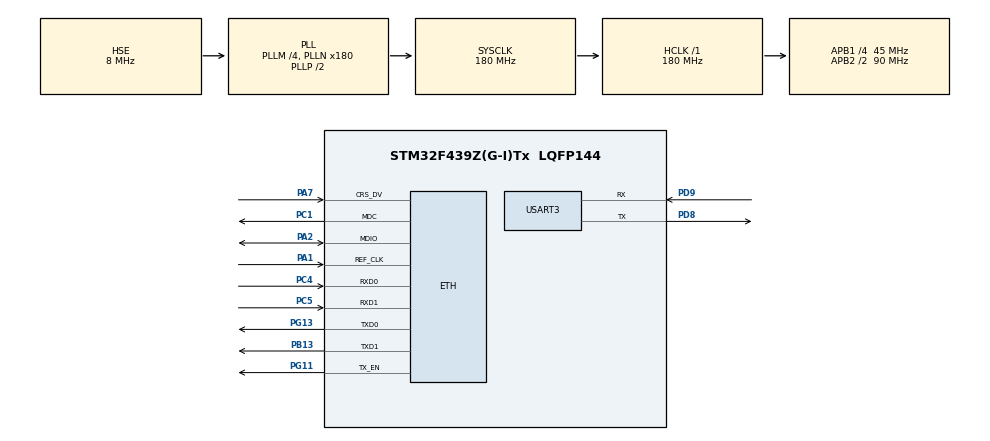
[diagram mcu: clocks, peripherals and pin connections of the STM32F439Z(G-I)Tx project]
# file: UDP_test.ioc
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ETH.MediaInterface=HAL_ETH_RMII_MODE
LWIP.BSP.number=1
LWIP.GATEWAY_ADDRESS=192.168.001.001
LWIP.IP_ADDRESS=192.168.001.102
LWIP.LWIP_DHCP=0
LWIP.LWIP_NETIF_STATUS_CALLBACK=1
LWIP.MEM_SIZE=16000
LWIP.NETMASK_ADDRESS=255.255.255.000
LWIP.Version=v2.1.2_Cube
LWIP0.BSP.STBoard=false
LWIP0.BSP.api=BSP_COMPONENT_DRIVER
LWIP0.BSP.component=LAN8742
LWIP0.BSP.instance=LAN8742
LWIP0.BSP.name=Driver_PHY
LWIP0.BSP.semaphore=S_LAN8742
LWIP0.BSP.solution=LAN8742
Mcu.Family=STM32F4
Mcu.Name=STM32F439Z(G-I)Tx
Mcu.Package=LQFP144
NVIC.ETH_IRQn=true\:0\:0\:false\:false\:true\:true\:true\:true
NVIC.PriorityGroup=NVIC_PRIORITYGROUP_4
NVIC.USART3_IRQn=true\:0\:0\:false\:false\:true\:true\:true\:true
PA1.Mode=RMII
PA1.Signal=ETH_REF_CLK
PA13.Mode=Serial_Wire
PA13.Signal=SYS_JTMS-SWDIO
PA14.Mode=Serial_Wire
PA14.Signal=SYS_JTCK-SWCLK
PA2.Mode=RMII
PA2.Signal=ETH_MDIO
PA7.Mode=RMII
PA7.Signal=ETH_CRS_DV
PB13.Mode=RMII
PB13.Signal=ETH_TXD1
PC1.Mode=RMII
PC1.Signal=ETH_MDC
PC14/OSC32_IN.Mode=LSE-External-Oscillator
PC14/OSC32_IN.Signal=RCC_OSC32_IN
PC15/OSC32_OUT.Mode=LSE-External-Oscillator
PC15/OSC32_OUT.Signal=RCC_OSC32_OUT
PC4.Mode=RMII
PC4.Signal=ETH_RXD0
PC5.Mode=RMII
PC5.Signal=ETH_RXD1
PD8.Mode=Asynchronous
PD8.Signal=USART3_TX
PD9.Mode=Asynchronous
PD9.Signal=USART3_RX
PG11.Mode=RMII
PG11.Signal=ETH_TX_EN
PG13.Mode=RMII
PG13.Signal=ETH_TXD0
PH0/OSC_IN.Mode=HSE-External-Clock-Source
PH0/OSC_IN.Signal=RCC_OSC_IN
PH1/OSC_OUT.Mode=HSE-External-Clock-Source
PH1/OSC_OUT.Signal=RCC_OSC_OUT
ProjectManager.HeapSize=0x200
ProjectManager.StackSize=0x400
ProjectManager.TargetToolchain=STM32CubeIDE
RCC.48MHZClocksFreq_Value=51428571.428571425
RCC.AHBFreq_Value=180000000
RCC.APB1CLKDivider=RCC_HCLK_DIV4
RCC.APB1Freq_Value=45000000
RCC.APB1TimFreq_Value=90000000
RCC.APB2CLKDivider=RCC_HCLK_DIV2
RCC.APB2Freq_Value=90000000
RCC.APB2TimFreq_Value=180000000
RCC.CortexFreq_Value=180000000
RCC.HCLKFreq_Value=180000000
RCC.HSE_VALUE=8000000
RCC.HSI_VALUE=16000000
RCC.PLLM=4
RCC.PLLMUL=RCC_PLL_MUL9
RCC.PLLN=180
RCC.PLLQ=7
RCC.PLLSourceVirtual=RCC_PLLSOURCE_HSE
RCC.PRESCALERUSB=RCC_USBCLKSOURCE_PLL_DIV1_5
RCC.SYSCLKFreq_VALUE=180000000
RCC.SYSCLKSource=RCC_SYSCLKSOURCE_PLLCLK
RCC.SYSCLKSourceVirtual=RCC_SYSCLKSOURCE_PLLCLK
RCC.USBFreq_Value=48000000
RCC.VCOOutputFreq_Value=360000000
USART3.VirtualMode=VM_ASYNC
VP_LWIP_VS_Enabled.Mode=Enabled
board=NUCLEO-F439ZI

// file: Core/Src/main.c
/* USER CODE BEGIN Header */
/**
  ******************************************************************************
  * @file           : main.c
  * @brief          : Main program body
  ******************************************************************************
  * @attention
  *
  * Copyright (c) 2026 STMicroelectronics.
  * All rights reserved.
  *
  * This software is licensed under terms that can be found in the LICENSE file
  * in the root directory of this software component.
  * If no LICENSE file comes with this software, it is provided AS-IS.
  *
  ******************************************************************************
  */
/* USER CODE END Header */
#include "main.h"
#include "lwip.h"

/* USER CODE BEGIN Includes */
#include "udp_server.h"
/* USER CODE END Includes */

/* USER CODE BEGIN PM */
#define ACK_INTERVAL_MS 1000  // Send ACK every 1 second

/* USER CODE END PM */

UART_HandleTypeDef huart3;

void SystemClock_Config(void);
static void MX_GPIO_Init(void);
static void MX_USART3_UART_Init(void);

int main(void)
{

  /* MCU Configuration--------------------------------------------------------*/

  /* Reset of all peripherals, Initializes the Flash interface and the Systick. */
  HAL_Init();

  /* Configure the system clock */
  SystemClock_Config();

  /* Initialize all configured peripherals */
  MX_GPIO_Init();
  MX_USART3_UART_Init();
  MX_LWIP_Init();
  /* USER CODE BEGIN 2 */
  udp_server_init();

      uint32_t last_ack_tick = 0;

      while (1)
      {
          /* Handle LWIP stack (process incoming UDP packets) */
          MX_LWIP_Process();

          /* Send periodic ACK to last client */
          uint32_t now = HAL_GetTick();
          if ((now - last_ack_tick) >= ACK_INTERVAL_MS)
          {
              last_ack_tick = now;
              udp_send_ack();
          }
      }
  /* USER CODE END 3 */
}

void SystemClock_Config(void)
{
  RCC_OscInitTypeDef RCC_OscInitStruct = {0};
  RCC_ClkInitTypeDef RCC_ClkInitStruct = {0};

  /** Configure the main internal regulator output voltage
  */
  __HAL_RCC_PWR_CLK_ENABLE();
  __HAL_PWR_VOLTAGESCALING_CONFIG(PWR_REGULATOR_VOLTAGE_SCALE1);

  /** Initializes the RCC Oscillators according to the specified parameters
  * in the RCC_OscInitTypeDef structure.
  */
  RCC_OscInitStruct.OscillatorType = RCC_OSCILLATORTYPE_HSE;
  RCC_OscInitStruct.HSEState = RCC_HSE_BYPASS;
  RCC_OscInitStruct.PLL.PLLState = RCC_PLL_ON;
  RCC_OscInitStruct.PLL.PLLSource = RCC_PLLSOURCE_HSE;
  RCC_OscInitStruct.PLL.PLLM = 4;
  RCC_OscInitStruct.PLL.PLLN = 180;
  RCC_OscInitStruct.PLL.PLLP = RCC_PLLP_DIV2;
  RCC_OscInitStruct.PLL.PLLQ = 7;
  if (HAL_RCC_OscConfig(&RCC_OscInitStruct) != HAL_OK)
  {
    Error_Handler();
  }

  /** Activate the Over-Drive mode
  */
  if (HAL_PWREx_EnableOverDrive() != HAL_OK)
  {
    Error_Handler();
  }

  /** Initializes the CPU, AHB and APB buses clocks
  */
  RCC_ClkInitStruct.ClockType = RCC_CLOCKTYPE_HCLK|RCC_CLOCKTYPE_SYSCLK
                              |RCC_CLOCKTYPE_PCLK1|RCC_CLOCKTYPE_PCLK2;
  RCC_ClkInitStruct.SYSCLKSource = RCC_SYSCLKSOURCE_PLLCLK;
  RCC_ClkInitStruct.AHBCLKDivider = RCC_SYSCLK_DIV1;
  RCC_ClkInitStruct.APB1CLKDivider = RCC_HCLK_DIV4;
  RCC_ClkInitStruct.APB2CLKDivider = RCC_HCLK_DIV2;

  if (HAL_RCC_ClockConfig(&RCC_ClkInitStruct, FLASH_LATENCY_5) != HAL_OK)
  {
    Error_Handler();
  }
}

static void MX_USART3_UART_Init(void)
{

  huart3.Instance = USART3;
  huart3.Init.BaudRate = 115200;
  huart3.Init.WordLength = UART_WORDLENGTH_8B;
  huart3.Init.StopBits = UART_STOPBITS_1;
  huart3.Init.Parity = UART_PARITY_NONE;
  huart3.Init.Mode = UART_MODE_TX_RX;
  huart3.Init.HwFlowCtl = UART_HWCONTROL_NONE;
  huart3.Init.OverSampling = UART_OVERSAMPLING_16;
  if (HAL_UART_Init(&huart3) != HAL_OK)
  {
    Error_Handler();
  }

}

static void MX_GPIO_Init(void)
{

  /* GPIO Ports Clock Enable */
  __HAL_RCC_GPIOC_CLK_ENABLE();
  __HAL_RCC_GPIOH_CLK_ENABLE();
  __HAL_RCC_GPIOA_CLK_ENABLE();
  __HAL_RCC_GPIOB_CLK_ENABLE();
  __HAL_RCC_GPIOD_CLK_ENABLE();
  __HAL_RCC_GPIOG_CLK_ENABLE();

}

void Error_Handler(void)
{
  __disable_irq();
  while (1)
  {
  }
}
